LIN_description_file;
LIN_protocol_version = "2.1";
LIN_language_version = "2.1";
LIN_speed = 19.2 kbps;

Nodes {
  Master: DEVM, 5.000 ms, 1.000 ms;
  Slaves: DEVS1, DEVS2;
}

Signals {
  SomeReq1: 2, 0, DEVM, DEVS1;
  SomePartNrDEVS2EndSgn1: 8, 0, DEVS2, DEVM;
  SomePartNrDEVS2EndSgn2: 8, 0, DEVS2, DEVM;
  SomePartNrDEVS2EndSgn3: 8, 0, DEVS2, DEVM;
  SomePartNrDEVS2Nr1: 8, 0, DEVS2, DEVM;
  SomePartNrDEVS2Nr2: 8, 0, DEVS2, DEVM;
  SomePartNrDEVS2Nr3: 8, 0, DEVS2, DEVM;
  SomePartNrDEVS2Nr4: 8, 0, DEVS2, DEVM;
  SomeChks: 2, 0, DEVM, DEVS2;
  SomeCntr: 2, 0, DEVM, DEVS2;
  counter: 2, 0, DEVM, DEVS2;
  SomeReq2Type2: 4, 8, DEVM, DEVS2;
  counter_times_2: 14, 0, DEVS1, DEVM;
  SomeQf: 2, 3, DEVS1, DEVM;
  ErrRespDEVS1: 1, 0, DEVS1, DEVM;
}

Frames {
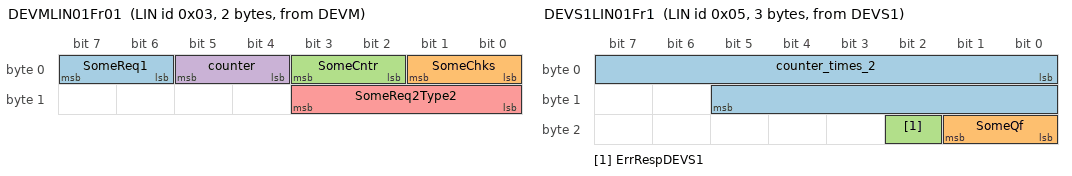
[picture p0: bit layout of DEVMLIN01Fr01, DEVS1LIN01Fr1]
  DEVMLIN01Fr01: 0x03, DEVM, 2 {
    SomeReq1, 6;
    SomeChks, 0;
    SomeCntr, 2;
    counter, 4;
    SomeReq2Type2, 8;
  }
  DEVS1LIN01Fr1: 0x05, DEVS1, 3 {
    counter_times_2, 0;
    SomeQf, 16;
    ErrRespDEVS1, 18;
  }
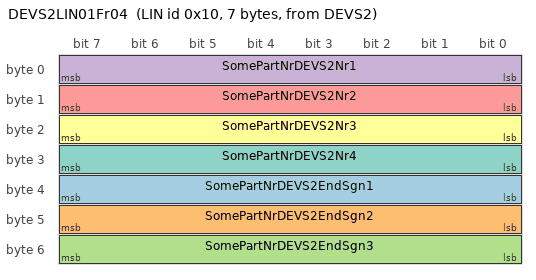
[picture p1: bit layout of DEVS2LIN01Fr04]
  DEVS2LIN01Fr04: 0x10, DEVS2, 7 {
    SomePartNrDEVS2EndSgn1, 32;
    SomePartNrDEVS2EndSgn2, 40;
    SomePartNrDEVS2EndSgn3, 48;
    SomePartNrDEVS2Nr1, 0;
    SomePartNrDEVS2Nr2, 8;
    SomePartNrDEVS2Nr3, 16;
    SomePartNrDEVS2Nr4, 24;
  }
}

Node_attributes {
  DEVS1 {
    LIN_protocol = "2.1";
    configured_NAD = 0x86;
    initial_NAD = 0x86;
    product_id = 0x7F, 0x204, 0;
    response_error = ErrRespDEVS1;
    configurable_frames {
      DEVMLIN01Fr01;
      DEVS1LIN01Fr1;
    }
  }
  DEVS2 {
    LIN_protocol = "2.1";
    configured_NAD = 0x81;
    initial_NAD = 0x81;
    product_id = 0x66, 0x15, 1;
    response_error = ErrRespDEVS2;
    configurable_frames {
      DEVMLIN01Fr01;
      DEVS2LIN01Fr04;
    }
  }
}

Schedule_tables {
  DEVMLIN01Schedule01 {
    DEVMLIN01Fr01 delay 10.000 ms;
    DEVS1LIN01Fr1 delay 10.000 ms;
    DEVMLIN01Fr01 delay 10.000 ms;
    DEVS1LIN01Fr1 delay 10.000 ms;
    DEVMLIN01Fr01 delay 10.000 ms;
    DEVS1LIN01Fr1 delay 10.000 ms;
    DEVS2LIN01Fr04 delay 10.000 ms;
  }
  DiagSchedule01 {
    MasterReq delay 15.000 ms;
    SlaveResp delay 15.000 ms;
  }
}

Signal_encoding_types {
  Boolean {
    logical_value, 0, "Boolean_FALSE";
    logical_value, 1, "Boolean_TRUE";
  }
  SomeQf1 {
    logical_value, 0, "SomeQf1_0";
    logical_value, 1, "SomeQf1_1";
    logical_value, 2, "SomeQf1_2";
    logical_value, 3, "SomeQf1_3";
  }
  TypeReq1 {
    logical_value, 0, "TypeReq1_mode0";
    logical_value, 1, "TypeReq1_mode1";
    logical_value, 2, "TypeReq1_mode2";
    logical_value, 3, "TypeReq1_mode3";
  }
  TypeReq2 {
    logical_value, 0, "TypeReq2_mode0";
    logical_value, 1, "TypeReq2_mode1";
    logical_value, 2, "TypeReq2_mode2";
    logical_value, 3, "TypeReq2_mode3";
  }
  SomeReq2Type2 {
    physical_value, 0, 15, 1.0, -8.0, "degC";
  }
  SomeReq31 {
    physical_value, 0, 10000, 1.0, 0.0, "NoUnit";
  }
  UInt2 {
    physical_value, 0, 3, 1.0, 0.0, "NoUnit";
  }
  UInt8 {
    physical_value, 0, 255, 1.0, 0.0, "NoUnit";
  }
}

Signal_representation {
  SomeQf1 : SomeQf;
  TypeReq1 : SomeReq1;
  TypeReq2 : counter;
  SomeReq2Type2 : SomeReq2Type2;
  SomeReq31 : counter_times_2;
  UInt2 : SomeChks, SomeCntr;
  UInt8 : SomePartNrDEVS2EndSgn1, SomePartNrDEVS2EndSgn2, SomePartNrDEVS2EndSgn3, SomePartNrDEVS2Nr1, SomePartNrDEVS2Nr2, SomePartNrDEVS2Nr3, SomePartNrDEVS2Nr4;
}
